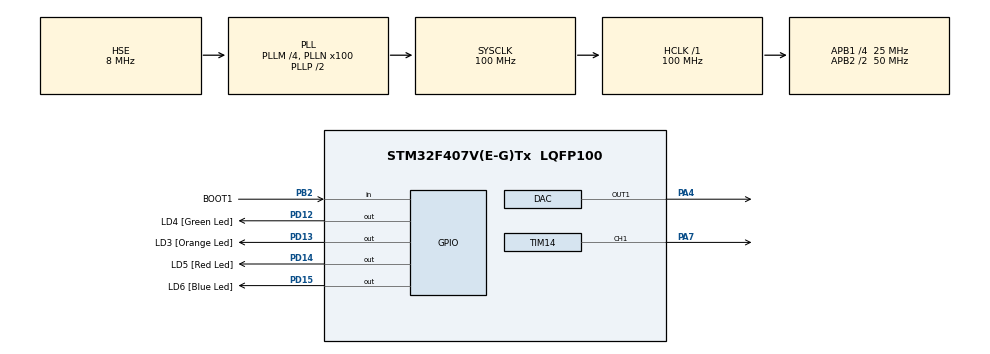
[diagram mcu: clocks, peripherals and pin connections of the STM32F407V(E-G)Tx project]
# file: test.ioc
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Mcu.Family=STM32F4
PD12.GPIO_Label=LD4 [Green Led]
PH0-OSC_IN.Signal=RCC_OSC_IN
RCC.CortexFreq_Value=100000000
NVIC.TIM6_DAC_IRQn=true\:0\:0\:false\:false\:true\:true\:true
PD15.GPIO_Speed=GPIO_SPEED_FREQ_LOW
PA14.GPIO_Label=SWCLK
PC15-OSC32_OUT.GPIO_Label=PC15-OSC32_OUT
RCC.SYSCLKSource=RCC_SYSCLKSOURCE_PLLCLK
ProjectManager.StackSize=0x400
VP_TIM7_VS_ClockSourceINT.Mode=Enable_Timer
PD13.Signal=GPIO_Output
PD14.GPIO_Speed=GPIO_SPEED_FREQ_LOW
SH.S_TIM14_CH1.0=TIM14_CH1,PWM Generation1 CH1
RCC.HCLKFreq_Value=100000000
RCC.APB2TimFreq_Value=100000000
TIM7.Period=3000 - 1
RCC.AHBFreq_Value=100000000
PH0-OSC_IN.Mode=HSE-External-Oscillator
PH0-OSC_IN.GPIO_Label=PH0-OSC_IN
RCC.HSE_VALUE=8000000
PB2.Signal=GPIO_Input
PB3.Mode=Trace_Asynchronous_SW
TIM14.Period=100 - 1
PC14-OSC32_IN.Mode=LSE-External-Oscillator
PA14.Mode=Trace_Asynchronous_SW
PD14.GPIO_PuPd=GPIO_NOPULL
PB2.GPIO_PuPd=GPIO_NOPULL
PH1-OSC_OUT.Mode=HSE-External-Oscillator
PD13.GPIO_Label=LD3 [Orange Led]
Mcu.Package=LQFP100
PD12.Signal=GPIO_Output
PD15.GPIO_PuPd=GPIO_NOPULL
RCC.APB2CLKDivider=RCC_HCLK_DIV2
RCC.APB1TimFreq_Value=50000000
PC14-OSC32_IN.GPIO_Label=PC14-OSC32_IN
VP_TIM14_VS_ClockSourceINT.Mode=Enable_Timer
PD15.Signal=GPIO_Output
NVIC.TIM7_IRQn=true\:0\:0\:false\:false\:true\:true\:true
PB3.GPIO_Label=SWO
RCC.PLLSourceVirtual=RCC_PLLSOURCE_HSE
PC15-OSC32_OUT.Mode=LSE-External-Oscillator
SH.COMP_DAC1_group.0=DAC_OUT1,DAC_OUT1
PD12.GPIO_Speed=GPIO_SPEED_FREQ_LOW
PD15.GPIO_Label=LD6 [Blue Led]
RCC.APB1CLKDivider=RCC_HCLK_DIV4
PC14-OSC32_IN.Signal=RCC_OSC32_IN
PA13.Signal=SYS_JTMS-SWDIO
ProjectManager.TargetToolchain=MDK-ARM V5.27
PC15-OSC32_OUT.Signal=RCC_OSC32_OUT
TIM7.Prescaler=5000 - 1
board=STM32F407G-DISC1
PD13.GPIO_Speed=GPIO_SPEED_FREQ_LOW
RCC.VCOOutputFreq_Value=200000000
RCC.APB2Freq_Value=50000000
PB2.GPIO_Mode=GPIO_MODE_INPUT
TIM14.Channel=TIM_CHANNEL_1
PH1-OSC_OUT.Signal=RCC_OSC_OUT
PD13.GPIO_PuPd=GPIO_NOPULL
PD14.GPIO_Label=LD5 [Red Led]
PH1-OSC_OUT.GPIO_Label=PH1-OSC_OUT
PA13.Mode=Trace_Asynchronous_SW
Mcu.Name=STM32F407V(E-G)Tx
TIM14.Prescaler=50 - 1
PA13.GPIO_Label=SWDIO
PD14.Signal=GPIO_Output
RCC.48MHZClocksFreq_Value=28571428.57142857
PB3.Signal=SYS_JTDO-SWO
PA4.Signal=COMP_DAC1_group
RCC.SYSCLKFreq_VALUE=100000000
PA14.Signal=SYS_JTCK-SWCLK
PB2.GPIO_Label=BOOT1
ProjectManager.HeapSize=0x200
RCC.HSI_VALUE=16000000
RCC.PLLQ=7
NVIC.PriorityGroup=NVIC_PRIORITYGROUP_0
RCC.PLLM=4
RCC.PLLN=100
RCC.APB1Freq_Value=25000000
PD12.GPIO_PuPd=GPIO_NOPULL
PA7.Signal=S_TIM14_CH1

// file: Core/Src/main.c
/* USER CODE BEGIN Header */
/**
  ******************************************************************************
  * @file           : main.c
  * @brief          : Main program body
  ******************************************************************************
  * @attention
  *
  * <h2><center>&copy; Copyright (c) 2021 STMicroelectronics.
  * All rights reserved.</center></h2>
  *
  * This software component is licensed by ST under BSD 3-Clause license,
  * the "License"; You may not use this file except in compliance with the
  * License. You may obtain a copy of the License at:
  *                        opensource.org/licenses/BSD-3-Clause
  *
  ******************************************************************************
  */
/* USER CODE END Header */
#include "main.h"
#include "dac.h"
#include "tim.h"
#include "gpio.h"

/* USER CODE BEGIN Includes */
#include <stdint.h>
#include "liftHandler.h"
#include "safetyHandler.h"
/* USER CODE END Includes */

void SystemClock_Config(void);

int main(void)
{

  /* MCU Configuration--------------------------------------------------------*/

  /* Reset of all peripherals, Initializes the Flash interface and the Systick. */
  HAL_Init();

  /* Configure the system clock */
  SystemClock_Config();

  /* Initialize all configured peripherals */
  MX_GPIO_Init();
  MX_TIM14_Init();
  MX_DAC_Init();
  MX_TIM7_Init();
  /* USER CODE BEGIN 2 */
	initLift();
  /* USER CODE END 2 */

  /* Infinite loop */
  /* USER CODE BEGIN WHILE */
  while (1)
  {
		handleEmergency();
    /* USER CODE END WHILE */

  }
}

void SystemClock_Config(void)
{
  RCC_OscInitTypeDef RCC_OscInitStruct = {0};
  RCC_ClkInitTypeDef RCC_ClkInitStruct = {0};

  /** Configure the main internal regulator output voltage
  */
  __HAL_RCC_PWR_CLK_ENABLE();
  __HAL_PWR_VOLTAGESCALING_CONFIG(PWR_REGULATOR_VOLTAGE_SCALE1);
  /** Initializes the RCC Oscillators according to the specified parameters
  * in the RCC_OscInitTypeDef structure.
  */
  RCC_OscInitStruct.OscillatorType = RCC_OSCILLATORTYPE_HSE;
  RCC_OscInitStruct.HSEState = RCC_HSE_ON;
  RCC_OscInitStruct.PLL.PLLState = RCC_PLL_ON;
  RCC_OscInitStruct.PLL.PLLSource = RCC_PLLSOURCE_HSE;
  RCC_OscInitStruct.PLL.PLLM = 4;
  RCC_OscInitStruct.PLL.PLLN = 100;
  RCC_OscInitStruct.PLL.PLLP = RCC_PLLP_DIV2;
  RCC_OscInitStruct.PLL.PLLQ = 7;
  if (HAL_RCC_OscConfig(&RCC_OscInitStruct) != HAL_OK)
  {
    Error_Handler();
  }
  /** Initializes the CPU, AHB and APB buses clocks
  */
  RCC_ClkInitStruct.ClockType = RCC_CLOCKTYPE_HCLK|RCC_CLOCKTYPE_SYSCLK
                              |RCC_CLOCKTYPE_PCLK1|RCC_CLOCKTYPE_PCLK2;
  RCC_ClkInitStruct.SYSCLKSource = RCC_SYSCLKSOURCE_PLLCLK;
  RCC_ClkInitStruct.AHBCLKDivider = RCC_SYSCLK_DIV1;
  RCC_ClkInitStruct.APB1CLKDivider = RCC_HCLK_DIV4;
  RCC_ClkInitStruct.APB2CLKDivider = RCC_HCLK_DIV2;

  if (HAL_RCC_ClockConfig(&RCC_ClkInitStruct, FLASH_LATENCY_3) != HAL_OK)
  {
    Error_Handler();
  }
}

void Error_Handler(void)
{
  __disable_irq();
  while (1)
  {
  }
}

/************************ (C) COPYRIGHT STMicroelectronics *****END OF FILE****/
